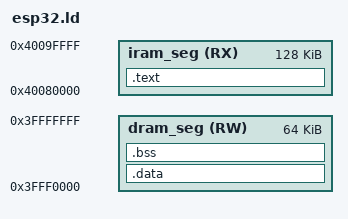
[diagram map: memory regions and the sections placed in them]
/* esp32.ld*/

/* Explicitly declares 'call_start_cpu0' (from boot.S) as the primary execution 
   entry point for the hardware binary image payload. */
ENTRY(call_start_cpu0)

/* Defines the physical layout and boundaries of the ESP32 internal memory blocks. */
MEMORY
{
    /* Allocates a 128 Kilobyte segment for Instruction RAM (iram), flagged as 
       Readable (R) and Executable (X), starting at address 0x40080000. */
    iram_seg (RX) : ORIGIN = 0x40080000, LENGTH = 128K
    /* Allocates a 64 Kilobyte segment for Data RAM (dram), flagged as 
       Readable (R) and Writable (W), starting at address 0x3FFF0000. */
    dram_seg (RW) : ORIGIN = 0x3FFF0000, LENGTH = 64K
}

/* Instructs the compiler how to group raw compilation artifacts (.o files) 
   into structural binary memory blocks. */
SECTIONS
{
    /* Defines the output '.text' block, which contains compile-ready machine instructions. */
    .text :
    {
        /* The dot (.) represents the current location counter. This aligns the 
           current memory address forward to a strict 4-byte boundary. */
        . = ALIGN(4);
        /* Forces the linker to retain the assembly entry code section from boot.S, 
           preventing dead-code elimination optimizations from stripping it away. */
        KEEP(*(.entry.text)) /* keep bootloder entry point alive */
        /* Gathers the primary machine instruction blocks (.text) from all compiled source objects. */
        *(.text)
        /* Gathers any wildcard sub-sections of machine instructions (like optimized functions). */
        *(.text*)
        /* Gathers the Xtensa-specific instruction constant pools (.literal) across all objects. */
        *(.literal)
        /* Gathers any wildcard sub-sections of constant literals generated by the compiler. */
        *(.literal*)
        /* Gathers read-only globally defined constants (e.g., const variables, string literals). */
        *(.rodata)
        /* Gathers any wildcard sub-sections of read-only constants. */
        *(.rodata*)
        /* Re-aligns the end of the instruction block cleanly to a 4-byte boundary. */
        . = ALIGN(4);
    } > iram_seg /* Directs the linker to load this entire combined block into Instruction RAM. */

    /* Defines the output '.data' block, containing initialized global and static variables. */
    .data :
    {
        /* Aligns the data memory block starting location counter to a 4-byte boundary. */
        . = ALIGN(4);
        /* Gathers variables that have explicit non-zero starting values (e.g., 'int x = 5;'). */
        *(.data)
        /* Gathers any wildcard sub-sections of initialized data variables. */
        *(.data*)
        /* Aligns the data memory block ending location counter to a 4-byte boundary. */
        . = ALIGN(4);
    } > dram_seg /* Directs the linker to load this mutable data block into Data RAM. */

    /* Defines the output '.bss' block, containing uninitialized global and static variables. */
    .bss :
    {
        /* Aligns the uninitialized data starting location counter to a 4-byte boundary. */
        . = ALIGN(4);
        /* Creates a tracking symbol '_sbss' (Start of BSS) at the exact current memory address, 
           allowing our assembly file (boot.S) to find out where to begin wiping memory. */
        _sbss = .;
        /* Gathers variables that have no explicit starting values (e.g., 'int x;'). */
        *(.bss)
        /* Gathers any wildcard sub-sections of uninitialized data variables. */
        *(.bss*)
        /* Gathers loose, unallocated standard common symbols from the compiler objects. */
        *(COMMON)
        /* Aligns the uninitialized data starting location counter to a 4-byte boundary. */
        . = ALIGN(4);
        /* Creates a tracking symbol '_ebss' (End of BSS) at the exact current memory address, 
           telling our assembly loop exactly where to stop wiping memory. */
        _ebss = .;
    } > dram_seg /* Directs the linker to load this mutable data block into Data RAM. */

    /* Calculates a final tracking symbol '_stack_top' by taking the base address of Data RAM 
       and adding its length, mapping the stack start pointer to the absolute top ceiling of DRAM. */
    _stack_top = ORIGIN(dram_seg) + LENGTH(dram_seg);
}
